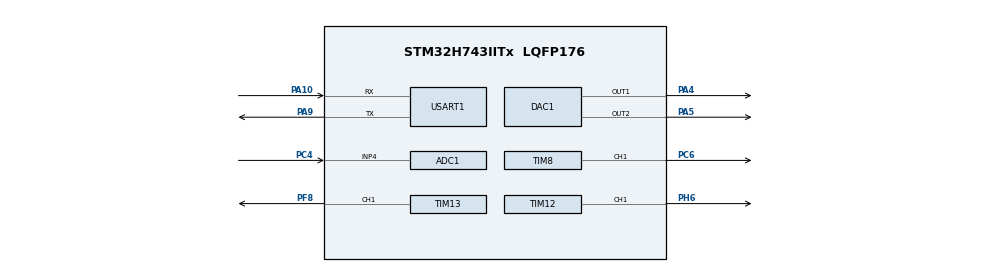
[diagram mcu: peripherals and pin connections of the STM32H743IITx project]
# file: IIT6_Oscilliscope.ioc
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ADC1.Channel-1\#ChannelRegularConversion=ADC_CHANNEL_4
ADC1.ConversionDataManagement=ADC_CONVERSIONDATA_DMA_ONESHOT
ADC1.ExternalTrigConv=ADC_EXTERNALTRIG_T3_TRGO
ADC1.NbrOfConversionFlag=1
ADC1.OffsetNumber-1\#ChannelRegularConversion=ADC_OFFSET_NONE
ADC1.OffsetSignedSaturation-1\#ChannelRegularConversion=DISABLE
ADC1.Rank-1\#ChannelRegularConversion=1
ADC1.SamplingTime-1\#ChannelRegularConversion=ADC_SAMPLETIME_1CYCLE_5
ADC1.master=1
CORTEX_M7.default_mode_Activation=1
DAC1.DAC1_OutputBuffer-DAC_OUT1=DAC_OUTPUTBUFFER_DISABLE
DAC1.DAC2_OutputBuffer-DAC_OUT2=DAC_OUTPUTBUFFER_DISABLE
DAC1.DAC_Channel-DAC_OUT1=DAC_CHANNEL_1
DAC1.DAC_Channel-DAC_OUT2=DAC_CHANNEL_2
DAC1.DAC_Trigger-DAC_OUT1=DAC_TRIGGER_T6_TRGO
DAC1.DAC_Trigger-DAC_OUT2=DAC_TRIGGER_T7_TRGO
Dma.ADC1.2.Direction=DMA_PERIPH_TO_MEMORY
Dma.ADC1.2.EventEnable=DISABLE
Dma.ADC1.2.FIFOMode=DMA_FIFOMODE_DISABLE
Dma.ADC1.2.Instance=DMA1_Stream2
Dma.ADC1.2.MemDataAlignment=DMA_MDATAALIGN_HALFWORD
Dma.ADC1.2.MemInc=DMA_MINC_ENABLE
Dma.ADC1.2.Mode=DMA_NORMAL
Dma.ADC1.2.PeriphDataAlignment=DMA_PDATAALIGN_HALFWORD
Dma.ADC1.2.PeriphInc=DMA_PINC_DISABLE
Dma.ADC1.2.Polarity=HAL_DMAMUX_REQ_GEN_RISING
Dma.ADC1.2.Priority=DMA_PRIORITY_LOW
Dma.ADC1.2.RequestNumber=1
Dma.ADC1.2.SignalID=NONE
Dma.ADC1.2.SyncEnable=DISABLE
Dma.ADC1.2.SyncPolarity=HAL_DMAMUX_SYNC_NO_EVENT
Dma.ADC1.2.SyncRequestNumber=1
Dma.ADC1.2.SyncSignalID=NONE
Dma.DAC1_CH1.0.Direction=DMA_MEMORY_TO_PERIPH
Dma.DAC1_CH1.0.EventEnable=DISABLE
Dma.DAC1_CH1.0.FIFOMode=DMA_FIFOMODE_ENABLE
Dma.DAC1_CH1.0.FIFOThreshold=DMA_FIFO_THRESHOLD_FULL
Dma.DAC1_CH1.0.Instance=DMA1_Stream0
Dma.DAC1_CH1.0.MemBurst=DMA_MBURST_SINGLE
Dma.DAC1_CH1.0.MemDataAlignment=DMA_MDATAALIGN_HALFWORD
Dma.DAC1_CH1.0.MemInc=DMA_MINC_ENABLE
Dma.DAC1_CH1.0.Mode=DMA_CIRCULAR
Dma.DAC1_CH1.0.PeriphBurst=DMA_PBURST_SINGLE
Dma.DAC1_CH1.0.PeriphDataAlignment=DMA_PDATAALIGN_HALFWORD
Dma.DAC1_CH1.0.PeriphInc=DMA_PINC_DISABLE
Dma.DAC1_CH1.0.Polarity=HAL_DMAMUX_REQ_GEN_RISING
Dma.DAC1_CH1.0.Priority=DMA_PRIORITY_LOW
Dma.DAC1_CH1.0.RequestNumber=1
Dma.DAC1_CH1.0.SignalID=NONE
Dma.DAC1_CH1.0.SyncEnable=DISABLE
Dma.DAC1_CH1.0.SyncPolarity=HAL_DMAMUX_SYNC_NO_EVENT
Dma.DAC1_CH1.0.SyncRequestNumber=1
Dma.DAC1_CH1.0.SyncSignalID=NONE
Dma.DAC1_CH2.1.Direction=DMA_MEMORY_TO_PERIPH
Dma.DAC1_CH2.1.EventEnable=DISABLE
Dma.DAC1_CH2.1.FIFOMode=DMA_FIFOMODE_ENABLE
Dma.DAC1_CH2.1.FIFOThreshold=DMA_FIFO_THRESHOLD_FULL
Dma.DAC1_CH2.1.Instance=DMA1_Stream1
Dma.DAC1_CH2.1.MemBurst=DMA_MBURST_SINGLE
Dma.DAC1_CH2.1.MemDataAlignment=DMA_MDATAALIGN_HALFWORD
Dma.DAC1_CH2.1.MemInc=DMA_MINC_ENABLE
Dma.DAC1_CH2.1.Mode=DMA_CIRCULAR
Dma.DAC1_CH2.1.PeriphBurst=DMA_PBURST_SINGLE
Dma.DAC1_CH2.1.PeriphDataAlignment=DMA_PDATAALIGN_HALFWORD
Dma.DAC1_CH2.1.PeriphInc=DMA_PINC_DISABLE
Dma.DAC1_CH2.1.Polarity=HAL_DMAMUX_REQ_GEN_RISING
Dma.DAC1_CH2.1.Priority=DMA_PRIORITY_LOW
Dma.DAC1_CH2.1.RequestNumber=1
Dma.DAC1_CH2.1.SignalID=NONE
Dma.DAC1_CH2.1.SyncEnable=DISABLE
Dma.DAC1_CH2.1.SyncPolarity=HAL_DMAMUX_SYNC_NO_EVENT
Dma.DAC1_CH2.1.SyncRequestNumber=1
Dma.DAC1_CH2.1.SyncSignalID=NONE
Dma.Request0=DAC1_CH1
Dma.Request1=DAC1_CH2
Dma.Request2=ADC1
Dma.Request3=USART1_TX
Dma.Request4=USART1_RX
Dma.Request5=TIM8_UP
Dma.TIM8_UP.5.Direction=DMA_MEMORY_TO_PERIPH
Dma.TIM8_UP.5.EventEnable=DISABLE
Dma.TIM8_UP.5.FIFOMode=DMA_FIFOMODE_DISABLE
Dma.TIM8_UP.5.Instance=DMA1_Stream6
Dma.TIM8_UP.5.MemDataAlignment=DMA_MDATAALIGN_HALFWORD
Dma.TIM8_UP.5.MemInc=DMA_MINC_ENABLE
Dma.TIM8_UP.5.Mode=DMA_CIRCULAR
Dma.TIM8_UP.5.PeriphDataAlignment=DMA_PDATAALIGN_HALFWORD
Dma.TIM8_UP.5.PeriphInc=DMA_PINC_DISABLE
Dma.TIM8_UP.5.Polarity=HAL_DMAMUX_REQ_GEN_RISING
Dma.TIM8_UP.5.Priority=DMA_PRIORITY_LOW
Dma.TIM8_UP.5.RequestNumber=1
Dma.TIM8_UP.5.SignalID=NONE
Dma.TIM8_UP.5.SyncEnable=DISABLE
Dma.TIM8_UP.5.SyncPolarity=HAL_DMAMUX_SYNC_NO_EVENT
Dma.TIM8_UP.5.SyncRequestNumber=1
Dma.TIM8_UP.5.SyncSignalID=NONE
Dma.USART1_RX.4.Direction=DMA_PERIPH_TO_MEMORY
Dma.USART1_RX.4.EventEnable=DISABLE
Dma.USART1_RX.4.FIFOMode=DMA_FIFOMODE_ENABLE
Dma.USART1_RX.4.FIFOThreshold=DMA_FIFO_THRESHOLD_FULL
Dma.USART1_RX.4.Instance=DMA1_Stream5
Dma.USART1_RX.4.MemBurst=DMA_MBURST_SINGLE
Dma.USART1_RX.4.MemDataAlignment=DMA_MDATAALIGN_BYTE
Dma.USART1_RX.4.MemInc=DMA_MINC_ENABLE
Dma.USART1_RX.4.Mode=DMA_NORMAL
Dma.USART1_RX.4.PeriphBurst=DMA_PBURST_SINGLE
Dma.USART1_RX.4.PeriphDataAlignment=DMA_PDATAALIGN_BYTE
Dma.USART1_RX.4.PeriphInc=DMA_PINC_DISABLE
Dma.USART1_RX.4.Polarity=HAL_DMAMUX_REQ_GEN_RISING
Dma.USART1_RX.4.Priority=DMA_PRIORITY_HIGH
Dma.USART1_RX.4.RequestNumber=1
Dma.USART1_RX.4.SignalID=NONE
Dma.USART1_RX.4.SyncEnable=DISABLE
Dma.USART1_RX.4.SyncPolarity=HAL_DMAMUX_SYNC_NO_EVENT
Dma.USART1_RX.4.SyncRequestNumber=1
Dma.USART1_RX.4.SyncSignalID=NONE
Dma.USART1_TX.3.Direction=DMA_MEMORY_TO_PERIPH
Dma.USART1_TX.3.EventEnable=DISABLE
Dma.USART1_TX.3.FIFOMode=DMA_FIFOMODE_ENABLE
Dma.USART1_TX.3.FIFOThreshold=DMA_FIFO_THRESHOLD_FULL
Dma.USART1_TX.3.Instance=DMA1_Stream4
Dma.USART1_TX.3.MemBurst=DMA_MBURST_SINGLE
Dma.USART1_TX.3.MemDataAlignment=DMA_MDATAALIGN_BYTE
Dma.USART1_TX.3.MemInc=DMA_MINC_ENABLE
Dma.USART1_TX.3.Mode=DMA_NORMAL
Dma.USART1_TX.3.PeriphBurst=DMA_PBURST_SINGLE
Dma.USART1_TX.3.PeriphDataAlignment=DMA_PDATAALIGN_BYTE
Dma.USART1_TX.3.PeriphInc=DMA_PINC_DISABLE
Dma.USART1_TX.3.Polarity=HAL_DMAMUX_REQ_GEN_RISING
Dma.USART1_TX.3.Priority=DMA_PRIORITY_HIGH
Dma.USART1_TX.3.RequestNumber=1
Dma.USART1_TX.3.SignalID=NONE
Dma.USART1_TX.3.SyncEnable=DISABLE
Dma.USART1_TX.3.SyncPolarity=HAL_DMAMUX_SYNC_NO_EVENT
Dma.USART1_TX.3.SyncRequestNumber=1
Dma.USART1_TX.3.SyncSignalID=NONE
FREERTOS.BinarySemaphores01=ADCSEM,Dynamic,NULL,Depleted;FFTSEM,Dynamic,NULL,Depleted;ADCFinishedSem,Dynamic,NULL,Depleted
FREERTOS.Queues01=UARTQueue,80,uint8_t,0,Dynamic,NULL,NULL;MSGQueue,16,APP_Text*,0,Dynamic,NULL,NULL
FREERTOS.Tasks01=defaultTask,24,128,StartDefaultTask,Default,NULL,Dynamic,NULL,NULL;UARTTask,48,128,StartUARTTask,As external,NULL,Dynamic,NULL,NULL;CMDTask,24,128,StartCMDTask,As external,NULL,Dynamic,NULL,NULL;ADCTask,30,128,StartADCTask,As external,NULL,Dynamic,NULL,NULL;FFTTask,29,1024,StartFFTTask,As external,NULL,Dynamic,NULL,NULL
Mcu.Family=STM32H7
Mcu.Name=STM32H743IITx
Mcu.Package=LQFP176
NVIC.DMA1_Stream0_IRQn=true\:5\:0\:false\:false\:true\:true\:false\:true\:true
NVIC.DMA1_Stream1_IRQn=true\:5\:0\:false\:false\:true\:true\:false\:true\:true
NVIC.DMA1_Stream2_IRQn=true\:5\:0\:false\:false\:true\:true\:false\:true\:true
NVIC.DMA1_Stream4_IRQn=true\:5\:0\:false\:false\:true\:true\:false\:true\:true
NVIC.DMA1_Stream5_IRQn=true\:5\:0\:false\:false\:true\:true\:false\:true\:true
NVIC.DMA1_Stream6_IRQn=true\:5\:0\:false\:false\:true\:true\:false\:true\:true
NVIC.PriorityGroup=NVIC_PRIORITYGROUP_4
NVIC.TIM1_UP_IRQn=true\:15\:0\:false\:false\:true\:false\:false\:true\:true
NVIC.TIM8_UP_TIM13_IRQn=true\:5\:0\:false\:false\:true\:false\:false\:true\:true
NVIC.TimeBase=TIM1_UP_IRQn
NVIC.TimeBaseIP=TIM1
NVIC.USART1_IRQn=true\:5\:0\:false\:false\:true\:true\:true\:true\:true
PA10.Mode=Asynchronous
PA10.Signal=USART1_RX
PA13\ (JTMS/SWDIO).Mode=Serial_Wire
PA13\ (JTMS/SWDIO).Signal=DEBUG_JTMS-SWDIO
PA14\ (JTCK/SWCLK).Mode=Serial_Wire
PA14\ (JTCK/SWCLK).Signal=DEBUG_JTCK-SWCLK
PA4.Signal=COMP_DAC11_group
PA5.Signal=COMP_DAC12_group
PA9.Mode=Asynchronous
PA9.Signal=USART1_TX
PB1.Signal=ADCx_INP5
PC14-OSC32_IN\ (OSC32_IN).Mode=LSE-External-Oscillator
PC14-OSC32_IN\ (OSC32_IN).Signal=RCC_OSC32_IN
PC15-OSC32_OUT\ (OSC32_OUT).Mode=LSE-External-Oscillator
PC15-OSC32_OUT\ (OSC32_OUT).Signal=RCC_OSC32_OUT
PC4.Signal=ADCx_INP4
PC6.Signal=S_TIM8_CH1
PF8.Signal=S_TIM13_CH1
PH0-OSC_IN\ (PH0).Mode=HSE-External-Oscillator
PH0-OSC_IN\ (PH0).Signal=RCC_OSC_IN
PH1-OSC_OUT\ (PH1).Mode=HSE-External-Oscillator
PH1-OSC_OUT\ (PH1).Signal=RCC_OSC_OUT
PH6.Signal=S_TIM12_CH1
ProjectManager.HeapSize=0x200
ProjectManager.StackSize=0x400
ProjectManager.TargetToolchain=CMake
RCC.ADCFreq_Value=75000000
RCC.APB1Freq_Value=120000000
RCC.APB2Freq_Value=120000000
RCC.APB3Freq_Value=120000000
RCC.APB4Freq_Value=120000000
RCC.CortexFreq_Value=480000000
RCC.D1PPRE=RCC_APB3_DIV2
RCC.D2PPRE1=RCC_APB1_DIV2
RCC.D2PPRE2=RCC_APB2_DIV2
RCC.D3PPRE=RCC_APB4_DIV2
RCC.DIVM1=5
RCC.DIVM2=2
RCC.DIVN1=192
RCC.DIVN2=12
RCC.HCLKFreq_Value=240000000
RCC.HPRE=RCC_HCLK_DIV2
RCC.PLLFRACN=0
RCC.PLLSourceVirtual=RCC_PLLSOURCE_HSE
RCC.SYSCLKFreq_VALUE=480000000
RCC.SYSCLKSource=RCC_SYSCLKSOURCE_PLLCLK
RCC.USBFreq_Value=480000000
SH.ADCx_INP4.0=ADC1_INP4,IN4-Single-Ended
SH.ADCx_INP5.0=ADC2_INP5
SH.COMP_DAC11_group.0=DAC1_OUT1,DAC_OUT1
SH.COMP_DAC12_group.0=DAC1_OUT2,DAC_OUT2
SH.S_TIM12_CH1.0=TIM12_CH1,PWM Generation1 CH1
SH.S_TIM13_CH1.0=TIM13_CH1,PWM Generation1 CH1
SH.S_TIM8_CH1.0=TIM8_CH1,PWM Generation1 CH1
STMicroelectronics.X-CUBE-ALGOBUILD.1.4.0.LibraryCcDSPOoLibraryJjDSPOoLibrary=true
TIM12.Channel-PWM\ Generation1\ CH1=TIM_CHANNEL_1
TIM12.Period=9
TIM12.Prescaler=23999
TIM12.Pulse-PWM\ Generation1\ CH1=4
TIM13.Channel=TIM_CHANNEL_1
TIM13.Period=9
TIM13.Prescaler=23
TIM13.Pulse=5
TIM3.Period=100-1
TIM3.Prescaler=240-1
TIM3.TIM_MasterOutputTrigger=TIM_TRGO_UPDATE
TIM6.Period=9
TIM6.Prescaler=23
TIM6.TIM_MasterOutputTrigger=TIM_TRGO_UPDATE
TIM7.Period=9
TIM7.Prescaler=23
TIM7.TIM_MasterOutputTrigger=TIM_TRGO_UPDATE
TIM8.Channel-PWM\ Generation1\ CH1=TIM_CHANNEL_1
TIM8.Period=2399
USART1.VirtualMode-Asynchronous=VM_ASYNC
VP_FREERTOS_VS_CMSIS_V2.Mode=CMSIS_V2
VP_MEMORYMAP_VS_MEMORYMAP.Mode=CurAppReg
VP_STMicroelectronics.X-CUBE-ALGOBUILD_VS_DSPOoLibraryJjLibrary_1.4.0_1.4.0.Mode=DSPOoLibraryJjLibrary
VP_SYS_VS_tim1.Mode=TIM1
VP_TIM12_VS_ClockSourceINT.Mode=Internal
VP_TIM13_VS_ClockSourceINT.Mode=Enable_Timer
VP_TIM3_VS_ClockSourceINT.Mode=Internal
VP_TIM6_VS_ClockSourceINT.Mode=Enable_Timer
VP_TIM7_VS_ClockSourceINT.Mode=Enable_Timer
VP_TIM8_VS_ClockSourceINT.Mode=Internal
board=custom

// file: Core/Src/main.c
/* USER CODE BEGIN Header */
/**
  ******************************************************************************
  * @file           : main.c
  * @brief          : Main program body
  ******************************************************************************
  * @attention
  *
  * Copyright (c) 2026 STMicroelectronics.
  * All rights reserved.
  *
  * This software is licensed under terms that can be found in the LICENSE file
  * in the root directory of this software component.
  * If no LICENSE file comes with this software, it is provided AS-IS.
  *
  ******************************************************************************
  */
/* USER CODE END Header */
#include "main.h"
#include "cmsis_os.h"
#include "adc.h"
#include "dac.h"
#include "dma.h"
#include "memorymap.h"
#include "tim.h"
#include "usart.h"
#include "gpio.h"

/* USER CODE BEGIN Includes */
#include "MSG.h"
/* USER CODE END Includes */

void SystemClock_Config(void);
static void MPU_Config(void);
void MX_FREERTOS_Init(void);

int main(void)
{

  /* MPU Configuration--------------------------------------------------------*/
  MPU_Config();

  /* MCU Configuration--------------------------------------------------------*/

  /* Reset of all peripherals, Initializes the Flash interface and the Systick. */
  HAL_Init();

  /* Configure the system clock */
  SystemClock_Config();

  /* Initialize all configured peripherals */
  MX_GPIO_Init();
  MX_DMA_Init();
  MX_DAC1_Init();
  MX_TIM6_Init();
  MX_TIM7_Init();
  MX_USART1_UART_Init();
  MX_TIM3_Init();
  MX_ADC1_Init();
  MX_TIM12_Init();
  MX_TIM13_Init();
  MX_TIM8_Init();

  /* Init scheduler */
  osKernelInitialize();

  /* Call init function for freertos objects (in cmsis_os2.c) */
  MX_FREERTOS_Init();

  /* Start scheduler */
  osKernelStart();

  /* We should never get here as control is now taken by the scheduler */

  /* Infinite loop */
  while (1)
  {

  }
}

void SystemClock_Config(void)
{
  RCC_OscInitTypeDef RCC_OscInitStruct = {0};
  RCC_ClkInitTypeDef RCC_ClkInitStruct = {0};

  /** Supply configuration update enable
  */
  HAL_PWREx_ConfigSupply(PWR_LDO_SUPPLY);

  /** Configure the main internal regulator output voltage
  */
  __HAL_PWR_VOLTAGESCALING_CONFIG(PWR_REGULATOR_VOLTAGE_SCALE0);

  while(!__HAL_PWR_GET_FLAG(PWR_FLAG_VOSRDY)) {}

  /** Initializes the RCC Oscillators according to the specified parameters
  * in the RCC_OscInitTypeDef structure.
  */
  RCC_OscInitStruct.OscillatorType = RCC_OSCILLATORTYPE_HSE;
  RCC_OscInitStruct.HSEState = RCC_HSE_ON;
  RCC_OscInitStruct.PLL.PLLState = RCC_PLL_ON;
  RCC_OscInitStruct.PLL.PLLSource = RCC_PLLSOURCE_HSE;
  RCC_OscInitStruct.PLL.PLLM = 5;
  RCC_OscInitStruct.PLL.PLLN = 192;
  RCC_OscInitStruct.PLL.PLLP = 2;
  RCC_OscInitStruct.PLL.PLLQ = 2;
  RCC_OscInitStruct.PLL.PLLR = 2;
  RCC_OscInitStruct.PLL.PLLRGE = RCC_PLL1VCIRANGE_2;
  RCC_OscInitStruct.PLL.PLLVCOSEL = RCC_PLL1VCOWIDE;
  RCC_OscInitStruct.PLL.PLLFRACN = 0;
  if (HAL_RCC_OscConfig(&RCC_OscInitStruct) != HAL_OK)
  {
    Error_Handler();
  }

  /** Initializes the CPU, AHB and APB buses clocks
  */
  RCC_ClkInitStruct.ClockType = RCC_CLOCKTYPE_HCLK|RCC_CLOCKTYPE_SYSCLK
                              |RCC_CLOCKTYPE_PCLK1|RCC_CLOCKTYPE_PCLK2
                              |RCC_CLOCKTYPE_D3PCLK1|RCC_CLOCKTYPE_D1PCLK1;
  RCC_ClkInitStruct.SYSCLKSource = RCC_SYSCLKSOURCE_PLLCLK;
  RCC_ClkInitStruct.SYSCLKDivider = RCC_SYSCLK_DIV1;
  RCC_ClkInitStruct.AHBCLKDivider = RCC_HCLK_DIV2;
  RCC_ClkInitStruct.APB3CLKDivider = RCC_APB3_DIV2;
  RCC_ClkInitStruct.APB1CLKDivider = RCC_APB1_DIV2;
  RCC_ClkInitStruct.APB2CLKDivider = RCC_APB2_DIV2;
  RCC_ClkInitStruct.APB4CLKDivider = RCC_APB4_DIV2;

  if (HAL_RCC_ClockConfig(&RCC_ClkInitStruct, FLASH_LATENCY_4) != HAL_OK)
  {
    Error_Handler();
  }
}

 /* MPU Configuration */

void MPU_Config(void)
{
  MPU_Region_InitTypeDef MPU_InitStruct = {0};

  /* Disables the MPU */
  HAL_MPU_Disable();

  /** Initializes and configures the Region and the memory to be protected
  */
  MPU_InitStruct.Enable = MPU_REGION_ENABLE;
  MPU_InitStruct.Number = MPU_REGION_NUMBER0;
  MPU_InitStruct.BaseAddress = 0x0;
  MPU_InitStruct.Size = MPU_REGION_SIZE_4GB;
  MPU_InitStruct.SubRegionDisable = 0x87;
  MPU_InitStruct.TypeExtField = MPU_TEX_LEVEL0;
  MPU_InitStruct.AccessPermission = MPU_REGION_NO_ACCESS;
  MPU_InitStruct.DisableExec = MPU_INSTRUCTION_ACCESS_DISABLE;
  MPU_InitStruct.IsShareable = MPU_ACCESS_SHAREABLE;
  MPU_InitStruct.IsCacheable = MPU_ACCESS_NOT_CACHEABLE;
  MPU_InitStruct.IsBufferable = MPU_ACCESS_NOT_BUFFERABLE;

  HAL_MPU_ConfigRegion(&MPU_InitStruct);
  /* Enables the MPU */
  HAL_MPU_Enable(MPU_PRIVILEGED_DEFAULT);

}

void HAL_TIM_PeriodElapsedCallback(TIM_HandleTypeDef *htim)
{
  if (htim->Instance == TIM1)
  {
    HAL_IncTick();
  }
}

void Error_Handler(void)
{
  __disable_irq();
  while (1)
  {
  }
}

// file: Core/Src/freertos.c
/* USER CODE BEGIN Header */
/**
  ******************************************************************************
  * File Name          : freertos.c
  * Description        : Code for freertos applications
  ******************************************************************************
  * @attention
  *
  * Copyright (c) 2026 STMicroelectronics.
  * All rights reserved.
  *
  * This software is licensed under terms that can be found in the LICENSE file
  * in the root directory of this software component.
  * If no LICENSE file comes with this software, it is provided AS-IS.
  *
  ******************************************************************************
  */
/* USER CODE END Header */

#include "FreeRTOS.h"
#include "task.h"
#include "main.h"
#include "cmsis_os.h"

/* USER CODE BEGIN Includes */
#include "MSG.h"
#include "protocol.h"
/* USER CODE END Includes */

/* Definitions for defaultTask */
osThreadId_t defaultTaskHandle;
const osThreadAttr_t defaultTask_attributes = {
  .name = "defaultTask",
  .stack_size = 128 * 4,
  .priority = (osPriority_t) osPriorityNormal,
};
/* Definitions for UARTTask */
osThreadId_t UARTTaskHandle;
const osThreadAttr_t UARTTask_attributes = {
  .name = "UARTTask",
  .stack_size = 128 * 4,
  .priority = (osPriority_t) osPriorityRealtime,
};
/* Definitions for CMDTask */
osThreadId_t CMDTaskHandle;
const osThreadAttr_t CMDTask_attributes = {
  .name = "CMDTask",
  .stack_size = 128 * 4,
  .priority = (osPriority_t) osPriorityNormal,
};
/* Definitions for ADCTask */
osThreadId_t ADCTaskHandle;
const osThreadAttr_t ADCTask_attributes = {
  .name = "ADCTask",
  .stack_size = 128 * 4,
  .priority = (osPriority_t) osPriorityNormal6,
};
/* Definitions for FFTTask */
osThreadId_t FFTTaskHandle;
const osThreadAttr_t FFTTask_attributes = {
  .name = "FFTTask",
  .stack_size = 1024 * 4,
  .priority = (osPriority_t) osPriorityNormal5,
};
/* Definitions for UARTQueue */
osMessageQueueId_t UARTQueueHandle;
const osMessageQueueAttr_t UARTQueue_attributes = {
  .name = "UARTQueue"
};
/* Definitions for MSGQueue */
osMessageQueueId_t MSGQueueHandle;
const osMessageQueueAttr_t MSGQueue_attributes = {
  .name = "MSGQueue"
};
/* Definitions for ADCSEM */
osSemaphoreId_t ADCSEMHandle;
const osSemaphoreAttr_t ADCSEM_attributes = {
  .name = "ADCSEM"
};
/* Definitions for FFTSEM */
osSemaphoreId_t FFTSEMHandle;
const osSemaphoreAttr_t FFTSEM_attributes = {
  .name = "FFTSEM"
};
/* Definitions for ADCFinishedSem */
osSemaphoreId_t ADCFinishedSemHandle;
const osSemaphoreAttr_t ADCFinishedSem_attributes = {
  .name = "ADCFinishedSem"
};

/* USER CODE BEGIN FunctionPrototypes */
void StartDefaultTask(void *argument);
extern void StartUARTTask(void *argument);
extern void StartCMDTask(void *argument);
extern void StartADCTask(void *argument);
/* USER CODE END FunctionPrototypes */

void StartDefaultTask(void *argument);
extern void StartUARTTask(void *argument);
extern void StartCMDTask(void *argument);
extern void StartADCTask(void *argument);
extern void StartFFTTask(void *argument);

void MX_FREERTOS_Init(void); /* (MISRA C 2004 rule 8.1) */

void MX_FREERTOS_Init(void) {

  /* Create the semaphores(s) */
  /* creation of ADCSEM */
  ADCSEMHandle = osSemaphoreNew(1, 0, &ADCSEM_attributes);

  /* creation of FFTSEM */
  FFTSEMHandle = osSemaphoreNew(1, 0, &FFTSEM_attributes);

  /* creation of ADCFinishedSem */
  ADCFinishedSemHandle = osSemaphoreNew(1, 0, &ADCFinishedSem_attributes);

  /* Create the queue(s) */
  /* creation of UARTQueue */
  UARTQueueHandle = osMessageQueueNew (80, sizeof(uint8_t), &UARTQueue_attributes);

  /* creation of MSGQueue */
  MSGQueueHandle = osMessageQueueNew (16, sizeof(APP_Text*), &MSGQueue_attributes);

  /* Create the thread(s) */
  /* creation of defaultTask */
  defaultTaskHandle = osThreadNew(StartDefaultTask, NULL, &defaultTask_attributes);

  /* creation of UARTTask */
  UARTTaskHandle = osThreadNew(StartUARTTask, NULL, &UARTTask_attributes);

  /* creation of CMDTask */
  CMDTaskHandle = osThreadNew(StartCMDTask, NULL, &CMDTask_attributes);

  /* creation of ADCTask */
  ADCTaskHandle = osThreadNew(StartADCTask, NULL, &ADCTask_attributes);

  /* creation of FFTTask */
  FFTTaskHandle = osThreadNew(StartFFTTask, NULL, &FFTTask_attributes);

}

void StartDefaultTask(void *argument)
{
  for(;;)
  {
    osDelay(1);
  }
}
